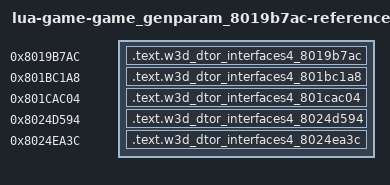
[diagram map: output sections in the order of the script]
/* Generated reference-only placements. All bodies are source-built. */
OUTPUT_FORMAT("elf32-powerpc")
OUTPUT_ARCH(powerpc)
ENTRY(w3d_dtor_interfaces4_8019b7ac)
_SDA_BASE_ = 0x804b2540;
_SDA2_BASE_ = 0x804c2540;
fn_801b4c6c = 0x801b4c6c;
fn_801bbb70 = 0x801bbb70;
fn_801c9134 = 0x801c9134;
fn_801ea138 = 0x801ea138;
fn_801ea740 = 0x801ea740;
fn_8024c144 = 0x8024c144;
w3d_vtable_80413530 = 0x80413530;
w3d_vtable_80415348 = 0x80415348;
w3d_vtable_80416280 = 0x80416280;
w3d_vtable_8041b7a8 = 0x8041b7a8;
w3d_vtable_8041b848 = 0x8041b848;
SECTIONS {
  .text.w3d_dtor_interfaces4_8019b7ac 0x8019b7ac : { *(.text.w3d_dtor_interfaces4_8019b7ac) }
  .text.w3d_dtor_interfaces4_801bc1a8 0x801bc1a8 : { *(.text.w3d_dtor_interfaces4_801bc1a8) }
  .text.w3d_dtor_interfaces4_801cac04 0x801cac04 : { *(.text.w3d_dtor_interfaces4_801cac04) }
  .text.w3d_dtor_interfaces4_8024d594 0x8024d594 : { *(.text.w3d_dtor_interfaces4_8024d594) }
  .text.w3d_dtor_interfaces4_8024ea3c 0x8024ea3c : { *(.text.w3d_dtor_interfaces4_8024ea3c) }
  /DISCARD/ : { *(.text*) *(.rodata*) *(.data*) *(.bss*) *(.sdata*) *(.sbss*) *(.comment) }
}
